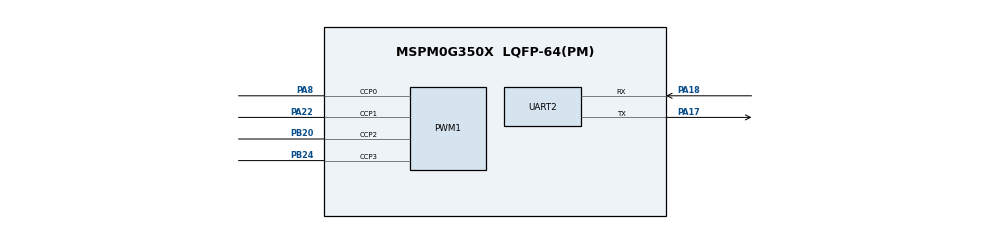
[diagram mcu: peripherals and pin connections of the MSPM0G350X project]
/**
 * @cliArgs --device "MSPM0G350X" --package "LQFP-64(PM)" --part "Default" --product "mspm0_sdk@2.01.00.03"
 * @versions {"tool":"1.20.0+3587"}
 */

/**
 * Import the modules used in this configuration.
 */
const GPIO   = scripting.addModule("/ti/driverlib/GPIO", {}, false);
const GPIO1  = GPIO.addInstance();
const GPIO2  = GPIO.addInstance();
const GPIO3  = GPIO.addInstance();
const GPIO4  = GPIO.addInstance();
const GPIO5  = GPIO.addInstance();
const GPIO6  = GPIO.addInstance();
const GPIO7  = GPIO.addInstance();
const GPIO8  = GPIO.addInstance();
const PWM    = scripting.addModule("/ti/driverlib/PWM", {}, false);
const PWM1   = PWM.addInstance();
const SYSCTL = scripting.addModule("/ti/driverlib/SYSCTL");
const TIMER  = scripting.addModule("/ti/driverlib/TIMER", {}, false);
const TIMER1 = TIMER.addInstance();
const UART   = scripting.addModule("/ti/driverlib/UART", {}, false);
const UART1  = UART.addInstance();
const UART2  = UART.addInstance();

/**
 * Write custom configuration values to the imported modules.
 */
GPIO1.$name                          = "GPIO_OLED";
GPIO1.associatedPins.create(2);
GPIO1.associatedPins[0].$name        = "OLED_SCL";
GPIO1.associatedPins[0].assignedPort = "PORTB";
GPIO1.associatedPins[0].assignedPin  = "17";
GPIO1.associatedPins[1].$name        = "OLED_SDA";
GPIO1.associatedPins[1].assignedPort = "PORTB";
GPIO1.associatedPins[1].assignedPin  = "18";

const Board = scripting.addModule("/ti/driverlib/Board", {}, false);

GPIO2.$name                               = "GPIO_Switch";
GPIO2.associatedPins.create(4);
GPIO2.associatedPins[0].direction         = "INPUT";
GPIO2.associatedPins[0].internalResistor  = "PULL_UP";
GPIO2.associatedPins[0].interruptEn       = true;
GPIO2.associatedPins[0].polarity          = "RISE";
GPIO2.associatedPins[0].assignedPort      = "PORTB";
GPIO2.associatedPins[0].assignedPin       = "21";
GPIO2.associatedPins[0].interruptPriority = "0";
GPIO2.associatedPins[0].$name             = "PIN_S1";
GPIO2.associatedPins[1].$name             = "PIN_S2";
GPIO2.associatedPins[1].direction         = "INPUT";
GPIO2.associatedPins[1].internalResistor  = "PULL_UP";
GPIO2.associatedPins[1].assignedPort      = "PORTB";
GPIO2.associatedPins[1].interruptEn       = true;
GPIO2.associatedPins[1].interruptPriority = "0";
GPIO2.associatedPins[1].polarity          = "RISE";
GPIO2.associatedPins[1].assignedPin       = "23";
GPIO2.associatedPins[2].$name             = "PIN_S3";
GPIO2.associatedPins[2].direction         = "INPUT";
GPIO2.associatedPins[2].polarity          = "RISE";
GPIO2.associatedPins[2].interruptEn       = true;
GPIO2.associatedPins[2].interruptPriority = "0";
GPIO2.associatedPins[2].assignedPort      = "PORTB";
GPIO2.associatedPins[2].assignedPin       = "26";
GPIO2.associatedPins[2].internalResistor  = "PULL_UP";
GPIO2.associatedPins[3].$name             = "PIN_S4";
GPIO2.associatedPins[3].assignedPort      = "PORTB";
GPIO2.associatedPins[3].assignedPin       = "27";
GPIO2.associatedPins[3].direction         = "INPUT";
GPIO2.associatedPins[3].interruptEn       = true;
GPIO2.associatedPins[3].polarity          = "RISE";
GPIO2.associatedPins[3].interruptPriority = "0";
GPIO2.associatedPins[3].internalResistor  = "PULL_UP";

GPIO3.$name                               = "GPIO_Encoder_Group1";
GPIO3.associatedPins.create(4);
GPIO3.associatedPins[0].$name             = "PIN_4";
GPIO3.associatedPins[0].direction         = "INPUT";
GPIO3.associatedPins[0].assignedPort      = "PORTB";
GPIO3.associatedPins[0].assignedPin       = "4";
GPIO3.associatedPins[0].interruptEn       = true;
GPIO3.associatedPins[0].polarity          = "RISE";
GPIO3.associatedPins[0].internalResistor  = "PULL_UP";
GPIO3.associatedPins[0].interruptPriority = "1";
GPIO3.associatedPins[1].$name             = "PIN_6";
GPIO3.associatedPins[1].direction         = "INPUT";
GPIO3.associatedPins[1].assignedPort      = "PORTB";
GPIO3.associatedPins[1].assignedPin       = "6";
GPIO3.associatedPins[1].interruptEn       = true;
GPIO3.associatedPins[1].polarity          = "RISE";
GPIO3.associatedPins[1].internalResistor  = "PULL_UP";
GPIO3.associatedPins[1].interruptPriority = "1";
GPIO3.associatedPins[2].$name             = "PIN_7";
GPIO3.associatedPins[2].internalResistor  = "PULL_UP";
GPIO3.associatedPins[2].assignedPort      = "PORTB";
GPIO3.associatedPins[2].assignedPin       = "7";
GPIO3.associatedPins[2].direction         = "INPUT";
GPIO3.associatedPins[2].interruptEn       = true;
GPIO3.associatedPins[2].polarity          = "RISE";
GPIO3.associatedPins[2].interruptPriority = "1";
GPIO3.associatedPins[3].$name             = "PIN_8";
GPIO3.associatedPins[3].direction         = "INPUT";
GPIO3.associatedPins[3].assignedPort      = "PORTB";
GPIO3.associatedPins[3].assignedPin       = "8";
GPIO3.associatedPins[3].interruptEn       = true;
GPIO3.associatedPins[3].polarity          = "RISE";
GPIO3.associatedPins[3].internalResistor  = "PULL_UP";
GPIO3.associatedPins[3].interruptPriority = "1";

GPIO4.$name                          = "GPIO_Motor_Group1";
GPIO4.associatedPins.create(4);
GPIO4.associatedPins[0].$name        = "PIN_M0_0";
GPIO4.associatedPins[0].initialValue = "SET";
GPIO4.associatedPins[0].assignedPort = "PORTB";
GPIO4.associatedPins[0].assignedPin  = "12";
GPIO4.associatedPins[1].$name        = "PIN_M0_1";
GPIO4.associatedPins[1].assignedPort = "PORTB";
GPIO4.associatedPins[1].assignedPin  = "13";
GPIO4.associatedPins[1].initialValue = "SET";
GPIO4.associatedPins[2].$name        = "PIN_M1_0";
GPIO4.associatedPins[2].assignedPort = "PORTB";
GPIO4.associatedPins[2].initialValue = "SET";
GPIO4.associatedPins[2].assignedPin  = "15";
GPIO4.associatedPins[3].$name        = "PIN_M1_1";
GPIO4.associatedPins[3].assignedPort = "PORTB";
GPIO4.associatedPins[3].assignedPin  = "16";
GPIO4.associatedPins[3].initialValue = "SET";

GPIO5.$name                          = "GPIO_Motor_Group2";
GPIO5.associatedPins.create(4);
GPIO5.associatedPins[0].$name        = "PIN_M2_0";
GPIO5.associatedPins[0].initialValue = "SET";
GPIO5.associatedPins[0].assignedPort = "PORTA";
GPIO5.associatedPins[0].assignedPin  = "14";
GPIO5.associatedPins[1].$name        = "PIN_M2_1";
GPIO5.associatedPins[1].initialValue = "SET";
GPIO5.associatedPins[1].assignedPort = "PORTA";
GPIO5.associatedPins[1].assignedPin  = "27";
GPIO5.associatedPins[2].$name        = "PIN_M3_0";
GPIO5.associatedPins[2].initialValue = "SET";
GPIO5.associatedPins[2].assignedPort = "PORTA";
GPIO5.associatedPins[2].assignedPin  = "15";
GPIO5.associatedPins[3].$name        = "PIN_M3_1";
GPIO5.associatedPins[3].initialValue = "SET";
GPIO5.associatedPins[3].assignedPort = "PORTA";
GPIO5.associatedPins[3].assignedPin  = "16";

GPIO6.$name                               = "GPIO_Encoder_Group2";
GPIO6.associatedPins.create(4);
GPIO6.associatedPins[0].$name             = "PIN_5";
GPIO6.associatedPins[0].assignedPort      = "PORTB";
GPIO6.associatedPins[0].assignedPin       = "5";
GPIO6.associatedPins[0].internalResistor  = "PULL_UP";
GPIO6.associatedPins[0].direction         = "INPUT";
GPIO6.associatedPins[0].interruptEn       = true;
GPIO6.associatedPins[0].polarity          = "FALL";
GPIO6.associatedPins[0].interruptPriority = "0";
GPIO6.associatedPins[1].assignedPort      = "PORTB";
GPIO6.associatedPins[1].assignedPin       = "22";
GPIO6.associatedPins[1].$name             = "PIN_22";
GPIO6.associatedPins[1].direction         = "INPUT";
GPIO6.associatedPins[1].internalResistor  = "PULL_UP";
GPIO6.associatedPins[1].interruptEn       = true;
GPIO6.associatedPins[1].interruptPriority = "0";
GPIO6.associatedPins[1].polarity          = "FALL";
GPIO6.associatedPins[2].$name             = "PIN_10";
GPIO6.associatedPins[2].direction         = "INPUT";
GPIO6.associatedPins[2].internalResistor  = "PULL_UP";
GPIO6.associatedPins[2].interruptEn       = true;
GPIO6.associatedPins[2].polarity          = "FALL";
GPIO6.associatedPins[2].interruptPriority = "0";
GPIO6.associatedPins[2].assignedPort      = "PORTB";
GPIO6.associatedPins[2].assignedPin       = "10";
GPIO6.associatedPins[3].$name             = "PIN_11";
GPIO6.associatedPins[3].assignedPort      = "PORTB";
GPIO6.associatedPins[3].assignedPin       = "11";
GPIO6.associatedPins[3].direction         = "INPUT";
GPIO6.associatedPins[3].internalResistor  = "PULL_UP";
GPIO6.associatedPins[3].interruptEn       = true;
GPIO6.associatedPins[3].polarity          = "FALL";
GPIO6.associatedPins[3].interruptPriority = "0";

GPIO7.$name                              = "GPIO_Sensor";
GPIO7.associatedPins.create(8);
GPIO7.associatedPins[0].$name            = "PIN_huidu1";
GPIO7.associatedPins[0].direction        = "INPUT";
GPIO7.associatedPins[0].internalResistor = "PULL_UP";
GPIO7.associatedPins[0].assignedPort     = "PORTA";
GPIO7.associatedPins[0].assignedPin      = "13";
GPIO7.associatedPins[1].$name            = "PIN_huidu2";
GPIO7.associatedPins[1].direction        = "INPUT";
GPIO7.associatedPins[1].internalResistor = "PULL_UP";
GPIO7.associatedPins[1].assignedPort     = "PORTA";
GPIO7.associatedPins[1].assignedPin      = "12";
GPIO7.associatedPins[2].$name            = "PIN_huidu3";
GPIO7.associatedPins[2].direction        = "INPUT";
GPIO7.associatedPins[2].internalResistor = "PULL_UP";
GPIO7.associatedPins[2].assignedPort     = "PORTA";
GPIO7.associatedPins[2].assignedPin      = "11";
GPIO7.associatedPins[3].internalResistor = "PULL_UP";
GPIO7.associatedPins[3].assignedPort     = "PORTA";
GPIO7.associatedPins[3].$name            = "PIN_huidu4";
GPIO7.associatedPins[3].direction        = "INPUT";
GPIO7.associatedPins[3].assignedPin      = "10";
GPIO7.associatedPins[4].$name            = "PIN_huidu5";
GPIO7.associatedPins[4].assignedPort     = "PORTA";
GPIO7.associatedPins[4].assignedPin      = "24";
GPIO7.associatedPins[4].internalResistor = "PULL_UP";
GPIO7.associatedPins[4].direction        = "INPUT";
GPIO7.associatedPins[5].assignedPort     = "PORTA";
GPIO7.associatedPins[5].assignedPin      = "25";
GPIO7.associatedPins[5].direction        = "INPUT";
GPIO7.associatedPins[5].internalResistor = "PULL_UP";
GPIO7.associatedPins[5].$name            = "PIN_huidu6";
GPIO7.associatedPins[6].$name            = "PIN_huidu0";
GPIO7.associatedPins[6].assignedPort     = "PORTA";
GPIO7.associatedPins[6].assignedPin      = "26";
GPIO7.associatedPins[6].internalResistor = "PULL_UP";
GPIO7.associatedPins[6].direction        = "INPUT";
GPIO7.associatedPins[7].$name            = "PIN_huidu7";
GPIO7.associatedPins[7].assignedPort     = "PORTA";
GPIO7.associatedPins[7].assignedPin      = "7";
GPIO7.associatedPins[7].internalResistor = "PULL_UP";
GPIO7.associatedPins[7].direction        = "INPUT";

GPIO8.$name                          = "GPIO_Sign";
GPIO8.associatedPins.create(2);
GPIO8.associatedPins[0].$name        = "PIN_LED";
GPIO8.associatedPins[0].initialValue = "SET";
GPIO8.associatedPins[0].assignedPort = "PORTB";
GPIO8.associatedPins[0].assignedPin  = "9";
GPIO8.associatedPins[1].$name        = "PIN_Bee";
GPIO8.associatedPins[1].initialValue = "SET";
GPIO8.associatedPins[1].assignedPort = "PORTB";
GPIO8.associatedPins[1].assignedPin  = "1";

PWM1.$name                              = "PWM_Motor";
PWM1.clockDivider                       = 8;
PWM1.clockPrescale                      = 4;
PWM1.timerCount                         = 100;
PWM1.timerStartTimer                    = true;
PWM1.pwmMode                            = "EDGE_ALIGN_UP";
PWM1.ccIndex                            = [0,1,2,3];
PWM1.peripheral.$assign                 = "TIMA0";
PWM1.peripheral.ccp0Pin.$assign         = "PA8";
PWM1.peripheral.ccp1Pin.$assign         = "PA22";
PWM1.peripheral.ccp2Pin.$assign         = "PB20";
PWM1.peripheral.ccp3Pin.$assign         = "PB24";
PWM1.PWM_CHANNEL_0.$name                = "ti_driverlib_pwm_PWMTimerCC0";
PWM1.PWM_CHANNEL_1.$name                = "ti_driverlib_pwm_PWMTimerCC1";
PWM1.ccp0PinConfig.$name                = "ti_driverlib_gpio_GPIOPinGeneric0";
PWM1.ccp0PinConfig.direction            = scripting.forceWrite("OUTPUT");
PWM1.ccp0PinConfig.hideOutputInversion  = scripting.forceWrite(false);
PWM1.ccp0PinConfig.onlyInternalResistor = scripting.forceWrite(false);
PWM1.ccp0PinConfig.passedPeripheralType = scripting.forceWrite("Digital");
PWM1.ccp1PinConfig.$name                = "ti_driverlib_gpio_GPIOPinGeneric1";
PWM1.ccp1PinConfig.direction            = scripting.forceWrite("OUTPUT");
PWM1.ccp1PinConfig.hideOutputInversion  = scripting.forceWrite(false);
PWM1.ccp1PinConfig.onlyInternalResistor = scripting.forceWrite(false);
PWM1.ccp1PinConfig.passedPeripheralType = scripting.forceWrite("Digital");
PWM1.PWM_CHANNEL_2.$name                = "ti_driverlib_pwm_PWMTimerCC2";
PWM1.PWM_CHANNEL_3.$name                = "ti_driverlib_pwm_PWMTimerCC3";
PWM1.ccp2PinConfig.$name                = "ti_driverlib_gpio_GPIOPinGeneric6";
PWM1.ccp3PinConfig.$name                = "ti_driverlib_gpio_GPIOPinGeneric7";

SYSCTL.forceDefaultClkConfig = true;

TIMER1.$name              = "TIMER_0";
TIMER1.timerClkPrescale   = 256;
TIMER1.timerMode          = "PERIODIC";
TIMER1.timerStartTimer    = true;
TIMER1.interrupts         = ["ZERO"];
TIMER1.interruptPriority  = "0";
TIMER1.timerPeriod        = "20ms";
TIMER1.peripheral.$assign = "TIMG0";

UART1.$name              = "UART_0";
UART1.enabledInterrupts  = ["TX"];
UART1.interruptPriority  = "1";
UART1.peripheral.$assign = "UART0";
UART1.txPinConfig.$name  = "ti_driverlib_gpio_GPIOPinGeneric2";
UART1.rxPinConfig.$name  = "ti_driverlib_gpio_GPIOPinGeneric3";

UART2.$name                            = "UART_gyro";
UART2.targetBaudRate                   = 115200;
UART2.enabledInterrupts                = ["RX"];
UART2.interruptPriority                = "0";
UART2.peripheral.rxPin.$assign         = "PA18";
UART2.peripheral.txPin.$assign         = "PA17";
UART2.txPinConfig.$name                = "ti_driverlib_gpio_GPIOPinGeneric4";
UART2.txPinConfig.direction            = scripting.forceWrite("OUTPUT");
UART2.txPinConfig.hideOutputInversion  = scripting.forceWrite(false);
UART2.txPinConfig.onlyInternalResistor = scripting.forceWrite(false);
UART2.txPinConfig.passedPeripheralType = scripting.forceWrite("Digital");
UART2.rxPinConfig.$name                = "ti_driverlib_gpio_GPIOPinGeneric5";
UART2.rxPinConfig.hideOutputInversion  = scripting.forceWrite(false);
UART2.rxPinConfig.onlyInternalResistor = scripting.forceWrite(false);
UART2.rxPinConfig.passedPeripheralType = scripting.forceWrite("Digital");

/**
 * Pinmux solution for unlocked pins/peripherals. This ensures that minor changes to the automatic solver in a future
 * version of the tool will not impact the pinmux you originally saw.  These lines can be completely deleted in order to
 * re-solve from scratch.
 */
GPIO1.associatedPins[0].pin.$suggestSolution = "PB17";
GPIO1.associatedPins[1].pin.$suggestSolution = "PB18";
Board.peripheral.$suggestSolution            = "DEBUGSS";
Board.peripheral.swclkPin.$suggestSolution   = "PA20";
Board.peripheral.swdioPin.$suggestSolution   = "PA19";
GPIO2.associatedPins[0].pin.$suggestSolution = "PB21";
GPIO2.associatedPins[1].pin.$suggestSolution = "PB23";
GPIO2.associatedPins[2].pin.$suggestSolution = "PB26";
GPIO2.associatedPins[3].pin.$suggestSolution = "PB27";
GPIO3.associatedPins[0].pin.$suggestSolution = "PB4";
GPIO3.associatedPins[1].pin.$suggestSolution = "PB6";
GPIO3.associatedPins[2].pin.$suggestSolution = "PB7";
GPIO3.associatedPins[3].pin.$suggestSolution = "PB8";
GPIO4.associatedPins[0].pin.$suggestSolution = "PB12";
GPIO4.associatedPins[1].pin.$suggestSolution = "PB13";
GPIO4.associatedPins[2].pin.$suggestSolution = "PB15";
GPIO4.associatedPins[3].pin.$suggestSolution = "PB16";
GPIO5.associatedPins[0].pin.$suggestSolution = "PA14";
GPIO5.associatedPins[1].pin.$suggestSolution = "PA27";
GPIO5.associatedPins[2].pin.$suggestSolution = "PA15";
GPIO5.associatedPins[3].pin.$suggestSolution = "PA16";
GPIO6.associatedPins[0].pin.$suggestSolution = "PB5";
GPIO6.associatedPins[1].pin.$suggestSolution = "PB22";
GPIO6.associatedPins[2].pin.$suggestSolution = "PB10";
GPIO6.associatedPins[3].pin.$suggestSolution = "PB11";
GPIO7.associatedPins[0].pin.$suggestSolution = "PA13";
GPIO7.associatedPins[1].pin.$suggestSolution = "PA12";
GPIO7.associatedPins[2].pin.$suggestSolution = "PA11";
GPIO7.associatedPins[3].pin.$suggestSolution = "PA10";
GPIO7.associatedPins[4].pin.$suggestSolution = "PA24";
GPIO7.associatedPins[5].pin.$suggestSolution = "PA25";
GPIO7.associatedPins[6].pin.$suggestSolution = "PA26";
GPIO7.associatedPins[7].pin.$suggestSolution = "PA7";
GPIO8.associatedPins[0].pin.$suggestSolution = "PB9";
GPIO8.associatedPins[1].pin.$suggestSolution = "PB1";
SYSCTL.peripheral.$suggestSolution           = "SYSCTL";
UART1.peripheral.rxPin.$suggestSolution      = "PA1";
UART1.peripheral.txPin.$suggestSolution      = "PA0";
UART2.peripheral.$suggestSolution            = "UART1";
